AUTOSAR XML (schema 00044)
package /ComponentTypes
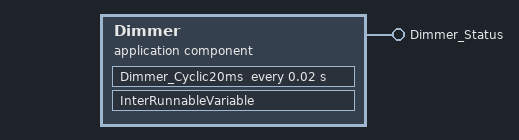
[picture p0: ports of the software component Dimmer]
  application sw component type Dimmer
    provide port Dimmer_Status: nonqueued-sender-com-spec{data-element=Element, init-value=100}, provided-interface=Dimmer_Status
    port group PortGroup: outer-ports=Dimmer_Status
    behavior Dimmer_InternalBehavior
      exclusive area ExclusiveArea
      timing event TMT_Dimmer_Cyclic20ms: start-on-event=Dimmer_Cyclic20ms, period=0.02
      explicit-inter-runnable-variables:
        data InterRunnableVariable: type=uint16, init-value=0
      runnable Dimmer_Cyclic20ms: can-enter-exclusive-area=ExclusiveArea, minimum-start-interval=5
        data-send-points:
          access SEND_Dimmer_Status_Element: accessed-variable=Dimmer_Status.Element
        written-local-variables:
          access WRITE_InterRunnableVariable: accessed-variable=InterRunnableVariable
      runnable InterRunnableVariable: can-enter-exclusive-area=ExclusiveArea
        read-local-variables:
          access Read_InterRunnableVariable: accessed-variable=InterRunnableVariable
      swc service dependency NvBlockNeed: category=SERVICE
        service-needs:
          nv block needs NvBlockNeed: n-data-sets=0, ram-block-status-control=API, reliability=NO-PROTECTION, restore-at-start=false, store-at-shutdown=false
      shared-parameters:
        parameter data prototype CalibrationParameter: sw-calibration-access=READ-WRITE, type=uint16, init-value=15
  swc implementation Dimmer_Implementation: behavior=Dimmer_InternalBehavior
